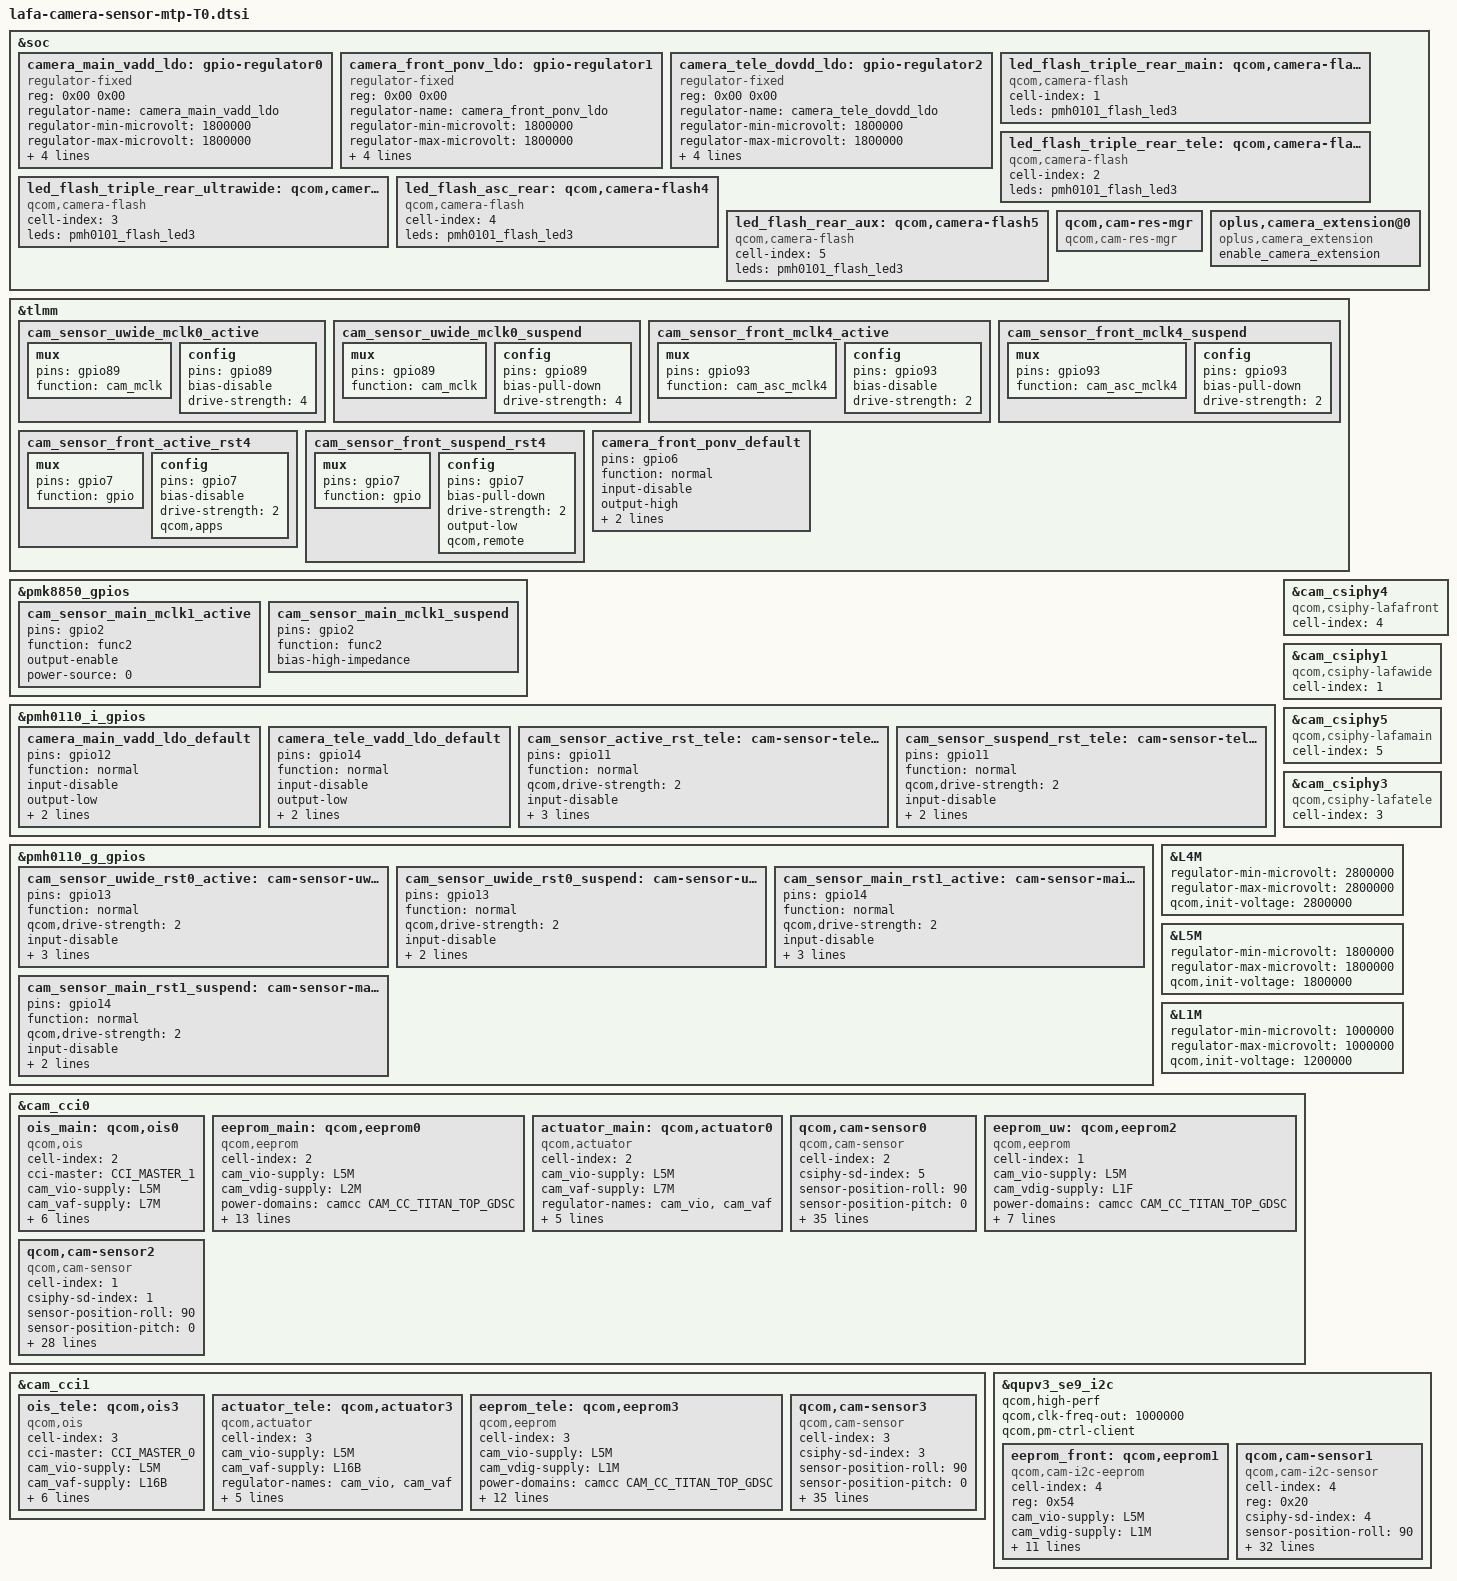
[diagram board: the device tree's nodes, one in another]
// SPDX-License-Identifier: BSD-3-Clause
/*
 * Copyright (c) 2024 Qualcomm Innovation Center, Inc. All rights reserved.
 */

#include <dt-bindings/msm-camera.h>
#include "ftm_camera_settings.dtsi"

&soc {

	camera_main_vadd_ldo: gpio-regulator0 {
		compatible = "regulator-fixed";
		reg = <0x00 0x00>;
		regulator-name = "camera_main_vadd_ldo";
		regulator-min-microvolt = <1800000>;
		regulator-max-microvolt = <1800000>;
		regulator-enable-ramp-delay = <135>;
		enable-active-high;
		gpio = <&pmh0110_i_gpios 12 0>;
		pinctrl-names = "default";
		pinctrl-0 = <&camera_main_vadd_ldo_default>;
	};

	camera_front_ponv_ldo: gpio-regulator1 {
		compatible = "regulator-fixed";
		reg = <0x00 0x00>;
		regulator-name = "camera_front_ponv_ldo";
		regulator-min-microvolt = <1800000>;
		regulator-max-microvolt = <1800000>;
		regulator-enable-ramp-delay = <135>;
		enable-active-high;
		gpio = <&tlmm 6 0>;
		pinctrl-names = "default";
		pinctrl-0 = <&camera_front_ponv_default>;
	};

	camera_tele_dovdd_ldo: gpio-regulator2 {
		compatible = "regulator-fixed";
		reg = <0x00 0x00>;
		regulator-name = "camera_tele_dovdd_ldo";
		regulator-min-microvolt = <1800000>;
		regulator-max-microvolt = <1800000>;
		regulator-enable-ramp-delay = <135>;
		enable-active-high;
		gpio = <&pmh0110_i_gpios 14 0>;
		pinctrl-names = "default";
		pinctrl-0 = <&camera_tele_vadd_ldo_default>;
	};

	led_flash_triple_rear_main: qcom,camera-flash1 {
		cell-index = <1>;
		compatible = "qcom,camera-flash";
		leds = <&pmh0101_flash_led3>;
		status = "ok";
	};

	led_flash_triple_rear_tele: qcom,camera-flash2 {
		cell-index = <2>;
		compatible = "qcom,camera-flash";
		leds = <&pmh0101_flash_led3>;
		status = "ok";
	};

	led_flash_triple_rear_ultrawide: qcom,camera-flash3 {
		cell-index = <3>;
		compatible = "qcom,camera-flash";
		leds = <&pmh0101_flash_led3>;
		status = "ok";
	};

	led_flash_asc_rear: qcom,camera-flash4 {
		cell-index = <4>;
		compatible = "qcom,camera-flash";
		leds = <&pmh0101_flash_led3>;
		status = "ok";
	};

	led_flash_rear_aux: qcom,camera-flash5 {
		cell-index = <5>;
		compatible = "qcom,camera-flash";
		leds = <&pmh0101_flash_led3>;
		status = "ok";
	};

	qcom,cam-res-mgr {
		compatible = "qcom,cam-res-mgr";
		status = "ok";
	};

	oplus,camera_extension@0 {
		compatible = "oplus,camera_extension";
		enable_camera_extension;
		status = "ok";
	};

};

&tlmm {

	cam_sensor_uwide_mclk0_active: cam_sensor_uwide_mclk0_active {
		/* MCLK0 */
		mux {
			pins = "gpio89";
			function = "cam_mclk";
		};

		config {
			pins = "gpio89";
			bias-disable; /* No PULL */
			drive-strength = <4>; /* 4 MA */
		};
	};

	cam_sensor_uwide_mclk0_suspend: cam_sensor_uwide_mclk0_suspend {
		/* MCLK0 */
		mux {
			pins = "gpio89";
			function = "cam_mclk";
		};

		config {
			pins = "gpio89";
			bias-pull-down; /* PULL DOWN */
			drive-strength = <4>; /* 4 MA */
		};
	};


	cam_sensor_front_mclk4_active: cam_sensor_front_mclk4_active {
		/* MCLK4 */
		mux {
			pins = "gpio93";
			function = "cam_asc_mclk4";
		};

		config {
			pins = "gpio93";
			bias-disable; /* No PULL */
			drive-strength = <2>; /* 2 MA */
		};
	};

	cam_sensor_front_mclk4_suspend: cam_sensor_front_mclk4_suspend {
		/* MCLK4 */
		mux {
			pins = "gpio93";
			function = "cam_asc_mclk4";
		};

		config {
			pins = "gpio93";
			bias-pull-down; /* PULL DOWN */
			drive-strength = <2>; /* 2 MA */
		};
	};

	cam_sensor_front_active_rst4: cam_sensor_front_active_rst4 {
		mux {
			pins = "gpio7";
			function = "gpio";
		};

		config {
			pins = "gpio7";
			bias-disable; /* No PULL */
			drive-strength = <2>; /* 2 MA */
			qcom,apps;
		};
	};

	cam_sensor_front_suspend_rst4: cam_sensor_front_suspend_rst4 {
		mux {
			pins = "gpio7";
			function = "gpio";
		};

		config {
			pins = "gpio7";
			bias-pull-down; /* PULL DOWN */
			drive-strength = <2>; /* 2 MA */
			output-low;
			qcom,remote;
		};
	};

 	camera_front_ponv_default: camera_front_ponv_default {
 		/* PONV */
 		pins = "gpio6";
 		function = "normal";
 		input-disable;
 		output-high;
 		power-source = <1>; /* 3.1V */
 		qcom,drive-strength = <2>;
 	};
};
&pmk8850_gpios {
	cam_sensor_main_mclk1_active: cam_sensor_main_mclk1_active {
			pins = "gpio2";
			function = "func2";
			output-enable;
			power-source = <0>; /* 1.8 V */
   };
	cam_sensor_main_mclk1_suspend: cam_sensor_main_mclk1_suspend {
 			pins = "gpio2";
 			function = "func2";
 			bias-high-impedance;
   };
};
&pmh0110_i_gpios {

	camera_main_vadd_ldo_default: camera_main_vadd_ldo_default {
		pins = "gpio12";
		function = "normal";
		input-disable;
		output-low;
		power-source = <1>; /* 2.8V */
		qcom,drive-strength = <2>;
	};
	camera_tele_vadd_ldo_default: camera_tele_vadd_ldo_default {
		pins = "gpio14";
		function = "normal";
		input-disable;
		output-low;
		power-source = <1>; /* 2.8V */
		qcom,drive-strength = <2>;
	};
	cam_sensor_active_rst_tele: cam-sensor-tele-active-state {
		pins = "gpio11";
		function = "normal";
		qcom,drive-strength = <2>;
		input-disable;
		output-enable;
		output-high;
		power-source = <0>; /* 1.8 V */
	};

	cam_sensor_suspend_rst_tele: cam-sensor-tele-suspend-state {
		pins = "gpio11";
		function = "normal";
		qcom,drive-strength = <2>;
		input-disable;
		output-enable;
		output-low;
	};
};

&pmh0110_g_gpios {

	cam_sensor_uwide_rst0_active: cam-sensor-uwide-rst0-active-state {
		pins = "gpio13";
		function = "normal";
		qcom,drive-strength = <2>;
		input-disable;
		output-enable;
		output-high;
		power-source = <0>; /* 1.8 V */
	};

	cam_sensor_uwide_rst0_suspend: cam-sensor-uwide-rst0-suspend-state {
		pins = "gpio13";
		function = "normal";
		qcom,drive-strength = <2>;
		input-disable;
		output-enable;
		output-low;
	};

	cam_sensor_main_rst1_active: cam-sensor-main-rst1-active-state {
		pins = "gpio14";
		function = "normal";
		qcom,drive-strength = <2>;
		input-disable;
		output-enable;
		output-high;
		power-source = <0>; /* 1.8 V */
	};

	cam_sensor_main_rst1_suspend: cam-sensor-main-rst1-suspend-state {
		pins = "gpio14";
		function = "normal";
		qcom,drive-strength = <2>;
		input-disable;
		output-enable;
		output-low;
	};
};

&cam_csiphy4{
        cell-index = <4>;
        compatible = "qcom,csiphy-lafafront", "qcom,csiphy";
};

&cam_csiphy1{
        cell-index = <1>;
        compatible = "qcom,csiphy-lafawide", "qcom,csiphy";
};

&cam_csiphy5{
        cell-index = <5>;
        compatible = "qcom,csiphy-lafamain", "qcom,csiphy";
};

&cam_csiphy3{
        cell-index = <3>;
        compatible = "qcom,csiphy-lafatele", "qcom,csiphy";
};

&L4M {
  regulator-min-microvolt = <2800000>;
  regulator-max-microvolt = <2800000>;
  qcom,init-voltage = <2800000>;
};

&L5M {
  regulator-min-microvolt = <1800000>;
  regulator-max-microvolt = <1800000>;
  qcom,init-voltage = <1800000>;
};
&L1M {
  regulator-min-microvolt = <1000000>;
  regulator-max-microvolt = <1000000>;
  qcom,init-voltage = <1200000>;
};
&cam_cci0 {
        ois_main: qcom,ois0 {
		cell-index = <2>;
		compatible = "qcom,ois";
		cci-master = <CCI_MASTER_1>;
		cam_vio-supply = <&L5M>;
		cam_vaf-supply = <&L7M>;
		power-domains = <&camcc CAM_CC_TITAN_TOP_GDSC>;
		regulator-names = "cam_vio","cam_vaf";
		rgltr-cntrl-support;
		rgltr-min-voltage = <1800000 2800000>;
		rgltr-max-voltage = <1800000 2800000>;
		rgltr-load-current = <6000 50000>;
		status = "ok";
	};

	eeprom_main: qcom,eeprom0 {
		cell-index = <2>;
		compatible = "qcom,eeprom";
		cam_vio-supply = <&L5M>;
		cam_vdig-supply = <&L2M>;
		power-domains = <&camcc CAM_CC_TITAN_TOP_GDSC>;
		cam_vana-supply = <&L4M>;
		cam_vaf-supply = <&L7M>;
		cam_v_custom1-supply = <&camera_main_vadd_ldo>;
		regulator-names = "cam_vio", "cam_vdig", "cam_vana",
			"cam_vaf", "cam_v_custom1";
		rgltr-cntrl-support;
		rgltr-min-voltage = <1800000 1100000 2800000 2800000 1800000>;
		rgltr-max-voltage = <1800000 1100000 2800000 2800000 1800000>;
		rgltr-load-current = <6000 12000 50000 50000 3000>;
		cci-master = <CCI_MASTER_1>;
		status = "ok";
	};

	actuator_main: qcom,actuator0 {
		cell-index = <2>;
		compatible = "qcom,actuator";
		cam_vio-supply = <&L5M>;
		cam_vaf-supply = <&L7M>;
		regulator-names = "cam_vio", "cam_vaf";
		rgltr-cntrl-support;
		rgltr-min-voltage = <1800000 2800000>;
		rgltr-max-voltage = <1800000 2800000>;
		rgltr-load-current = <6000 50000>;
		cci-master = <CCI_MASTER_1>;
		status = "ok";
	};

	qcom,cam-sensor0 {
		cell-index = <2>;
		compatible = "qcom,cam-sensor";
		csiphy-sd-index = <5>;
		sensor-position-roll = <90>;
		sensor-position-pitch = <0>;
		sensor-position-yaw = <180>;
		eeprom-src = <&eeprom_main>;
		actuator-src = <&actuator_main>;
		ois-src = <&ois_main>;
		led-flash-src = <&led_flash_triple_rear_main>;
		cam_vio-supply = <&L5M>;
		cam_vdig-supply = <&L2M>;
		power-domains = <&camcc CAM_CC_TITAN_TOP_GDSC>;
		cam_vana-supply = <&L4M>;
		cam_vaf-supply = <&L7M>;
		cam_v_custom1-supply = <&camera_main_vadd_ldo>;
		regulator-names = "cam_vio", "cam_vdig", "cam_vana",
			"cam_vaf", "cam_v_custom1";
		rgltr-cntrl-support;
		rgltr-min-voltage = <1800000 1100000 2800000 2800000 1800000>;
		rgltr-max-voltage = <1800000 1100000 2800000 2800000 1800000>;
		rgltr-load-current = <6000 12000 50000 50000 3000>;
		gpio-no-mux = <0>;
		pinctrl-names = "cam_default", "cam_suspend";
		pinctrl-0 = <&cam_sensor_main_mclk1_active
				 &cam_sensor_main_rst1_active>;
		pinctrl-1 = <&cam_sensor_main_mclk1_suspend
				 &cam_sensor_main_rst1_suspend>;
		gpios = <&pmh0110_g_gpios 14 0>;
		gpio-reset = <0>;
		gpio-req-tbl-num = <0>;
		gpio-req-tbl-flags = <0>;
		gpio-req-tbl-label = "CAM_RESET1";
		cci-master = <CCI_MASTER_1>;
                clocks = <&rpmhcc RPMH_DIV_CLK1>;
		clock-names = "cam_clk";
		clock-cntl-level = "nominal";
		clock-rates = <19200000>;
                ftm_setting_compatible = <'R' 0x0016 2 2 0x0906>;
		status = "ok";
	};

	eeprom_uw: qcom,eeprom2 {
		cell-index = <1>;
		compatible = "qcom,eeprom";
		cam_vio-supply = <&L5M>;
		cam_vdig-supply = <&L1F>;
		power-domains = <&camcc CAM_CC_TITAN_TOP_GDSC>;
		cam_vana-supply = <&L3M>;
		regulator-names = "cam_vio", "cam_vdig", "cam_vana";
		rgltr-cntrl-support;
		rgltr-min-voltage = <1800000 1200000 2800000>;
		rgltr-max-voltage = <1800000 1200000 2800000>;
		rgltr-load-current = <600000 12000 50000>;
		cci-master = <CCI_MASTER_0>;
		status = "ok";
	};

	qcom,cam-sensor2 {
		cell-index = <1>;
		compatible = "qcom,cam-sensor";
		csiphy-sd-index = <1>;
		sensor-position-roll = <90>;
		sensor-position-pitch = <0>;
		sensor-position-yaw = <180>;
		eeprom-src = <&eeprom_uw>;
		led-flash-src = <&led_flash_triple_rear_ultrawide>;
		cam_vio-supply = <&L5M>;
		cam_vdig-supply = <&L1F>;
		power-domains = <&camcc CAM_CC_TITAN_TOP_GDSC>;
		cam_vana-supply = <&L3M>;
		regulator-names = "cam_vio", "cam_vdig", "cam_vana";
		rgltr-cntrl-support;
		rgltr-min-voltage = <1800000 1200000 2800000>;
		rgltr-max-voltage = <1800000 1200000 2800000>;
		rgltr-load-current = <600000 12000 50000>;
		gpio-no-mux = <0>;
		pinctrl-names = "cam_default", "cam_suspend";
		pinctrl-0 = <&cam_sensor_uwide_mclk0_active
				 &cam_sensor_uwide_rst0_active>;
		pinctrl-1 = <&cam_sensor_uwide_mclk0_suspend
				 &cam_sensor_uwide_rst0_suspend>;
		gpios = <&tlmm 89 0>,
			<&pmh0110_g_gpios 13 0>;
		gpio-reset = <1>;
		gpio-req-tbl-num = <0 1>;
		gpio-req-tbl-flags = <1 0>;
		gpio-req-tbl-label = "CAMIF_MCLK0",
			"CAM_RESET0";
		cci-master = <CCI_MASTER_0>;
		clocks = <&cambistmclkcc CAM_BIST_MCLK_CC_MCLK0_CLK>;
		clock-names = "cam_clk";
		clock-cntl-level = "nominal";
		clock-rates = <19200000>;
                ftm_setting_compatible = <'R' 0x300B 2 2 0x5044>;
		status = "ok";
	};
};
//TELE
&cam_cci1 {
        ois_tele: qcom,ois3 {
		cell-index = <3>;
		compatible = "qcom,ois";
		cci-master = <CCI_MASTER_0>;
		cam_vio-supply = <&L5M>;
		cam_vaf-supply = <&L16B>;
		power-domains = <&camcc CAM_CC_TITAN_TOP_GDSC>;
		regulator-names = "cam_vio","cam_vaf";
		rgltr-cntrl-support;
		rgltr-min-voltage = <1800000 2800000>;
		rgltr-max-voltage = <1800000 2800000>;
		rgltr-load-current = <60000 300000>;
		status = "ok";
	};

        actuator_tele: qcom,actuator3 {
                cell-index = <3>;
                compatible = "qcom,actuator";
                cam_vio-supply = <&L5M>;
                cam_vaf-supply = <&L16B>;
                regulator-names = "cam_vio", "cam_vaf";
                rgltr-cntrl-support;
                rgltr-min-voltage = <1800000 2800000>;
                rgltr-max-voltage = <1800000 2800000>;
                rgltr-load-current = <60000 300000>;
                cci-master = <CCI_MASTER_0>;
                status = "ok";
        };

	eeprom_tele: qcom,eeprom3 {
		cell-index = <3>;
		compatible = "qcom,eeprom";
		cam_vio-supply = <&L5M>;
		cam_vdig-supply = <&L1M>;
		power-domains = <&camcc CAM_CC_TITAN_TOP_GDSC>;
		cam_vana-supply = <&L6M>;
		cam_vaf-supply = <&L16B>;
		regulator-names = "cam_vio", "cam_vdig",
			 "cam_vana", "cam_vaf";
		rgltr-cntrl-support;
		rgltr-min-voltage = <1800000 1000000 2200000 2800000>;
		rgltr-max-voltage = <1800000 1000000 2200000 2800000>;
		rgltr-load-current = <600000 1200000 300000 300000>;

		cci-master = <CCI_MASTER_0>;
		status = "ok";
	};
	qcom,cam-sensor3 {
		cell-index = <3>;
		compatible = "qcom,cam-sensor";
		csiphy-sd-index = <3>;
		sensor-position-roll = <90>;
		sensor-position-pitch = <0>;
		sensor-position-yaw = <180>;
                actuator-src = <&actuator_tele>;
		eeprom-src = <&eeprom_tele>;
                ois-src = <&ois_tele>;
		led-flash-src = <&led_flash_triple_rear_tele>;
		cam_vio-supply = <&L5M>;
		cam_vdig-supply = <&L1M>;
		power-domains = <&camcc CAM_CC_TITAN_TOP_GDSC>;
		cam_vana-supply = <&L6M>;
		cam_vaf-supply = <&L16B>;
		regulator-names = "cam_vio", "cam_vdig",
			 "cam_vana", "cam_vaf";
		rgltr-cntrl-support;
		rgltr-min-voltage = <1800000 1000000 2200000 2800000>;
		rgltr-max-voltage = <1800000 1000000 2200000 2800000>;
		rgltr-load-current = <600000 1200000 300000 300000>;
		gpio-no-mux = <0>;
		pinctrl-names = "cam_default", "cam_suspend";
		pinctrl-0 = <&cam_sensor_mclk3_active
				 &cam_sensor_active_rst_tele>;
		pinctrl-1 = <&cam_sensor_mclk3_suspend
				 &cam_sensor_suspend_rst_tele>;
		gpios = <&tlmm 92 0>,
			<&pmh0110_i_gpios 11 0>;
		gpio-reset = <1>;
		gpio-req-tbl-num = <0 1>;
		gpio-req-tbl-flags = <1 0>;
		gpio-req-tbl-label = "CAMIF_MCLK3",
					"CAM_RESET3";
		cci-master = <CCI_MASTER_0>;
		clocks = <&cambistmclkcc CAM_BIST_MCLK_CC_MCLK3_CLK>;
		clock-names = "cam_clk";
		clock-cntl-level = "nominal";
		clock-rates = <19200000>;
                ftm_setting_compatible = <'R' 0x0000 2 2 0x1B75>;
		status = "ok";
	};
};

&qupv3_se9_i2c {
	status = "ok";
	qcom,high-perf;
	qcom,clk-freq-out = <1000000>;
	qcom,pm-ctrl-client;

	eeprom_front: qcom,eeprom1 {
		cell-index = <4>;
		reg = <0x54>;
		compatible = "qcom,cam-i2c-eeprom";
		cam_vio-supply = <&L5M>;
	        cam_vdig-supply = <&L1M>;
		power-domains = <&camcc CAM_CC_TITAN_TOP_GDSC>;
		cam_vana-supply = <&L3M>;
	        cam_v_custom1-supply = <&camera_front_ponv_ldo>;
		regulator-names = "cam_vio", "cam_vdig", "cam_vana", "cam_v_custom1";
		rgltr-cntrl-support;
		rgltr-min-voltage = <1800000 1000000 2800000 1800000>;
		rgltr-max-voltage = <1800000 1000000 2800000 1800000>;
		rgltr-load-current = <3000   3000     50000    3000>;
		status = "ok";
	};

	 qcom,cam-sensor1 {
		cell-index = <4>;
		reg = <0x20>;
		compatible = "qcom,cam-i2c-sensor";
		csiphy-sd-index = <4>;
		sensor-position-roll = <90>;
		sensor-position-pitch = <0>;
		sensor-position-yaw = <0>;
		eeprom-src = <&eeprom_front>;
		cam_vio-supply = <&L5M>;
	        cam_vdig-supply = <&L1M>;
		power-domains = <&camcc CAM_CC_TITAN_TOP_GDSC>;
		cam_vana-supply = <&L3M>;
	        cam_v_custom1-supply = <&camera_front_ponv_ldo>;
		regulator-names = "cam_vio", "cam_vdig", "cam_vana", "cam_v_custom1";
		rgltr-cntrl-support;
		aon-camera-id = <AON_CAM1>;
		rgltr-min-voltage = <1800000 1000000 2800000 1800000>;
		rgltr-max-voltage = <1800000 1000000 2800000 1800000>;
		rgltr-load-current = <3000  3000  50000   3000>;
		gpio-no-mux = <0>;
		pinctrl-names = "cam_default", "cam_suspend";
		pinctrl-0 = <&cam_sensor_front_mclk4_active
				 &cam_sensor_front_active_rst4>;
		pinctrl-1 = <&cam_sensor_front_mclk4_suspend
				 &cam_sensor_front_suspend_rst4>;
		gpios = <&tlmm 93 0>,
			<&tlmm 7 0>;
		gpio-reset = <1>;
		gpio-req-tbl-num = <0 1>;
		gpio-req-tbl-flags = <1 0>;
		gpio-req-tbl-label = "CAMIF_MCLK4",
					"CAM_RESET4";
		clocks = <&cambistmclkcc CAM_BIST_MCLK_CC_MCLK4_CLK>;
		clock-names = "cam_clk";
		clock-cntl-level = "nominal";
		clock-rates = <19200000>;
                ftm_setting_compatible = <'R' 0x03F0 2 2 0x32E2>;
		status = "ok";
	};
};
